# dm646x_cslr_vdce register map
Vendor: Texas Instruments
Peripheral module from a debugger description file.
Registers are 32-bit, access not given, reset 0x0 unless marked. A register's access mark holds for its fields unless they carry their own. Offsets are as the file gives them; lines under a group give offsets from that group; [hi:lo] are bit positions; {n}, {i} and the like mark numbered series; 'fields as' and 'values as' point back to an identical list; <NAME> marks a mode.

## VDCE — Registers for the VDCE module
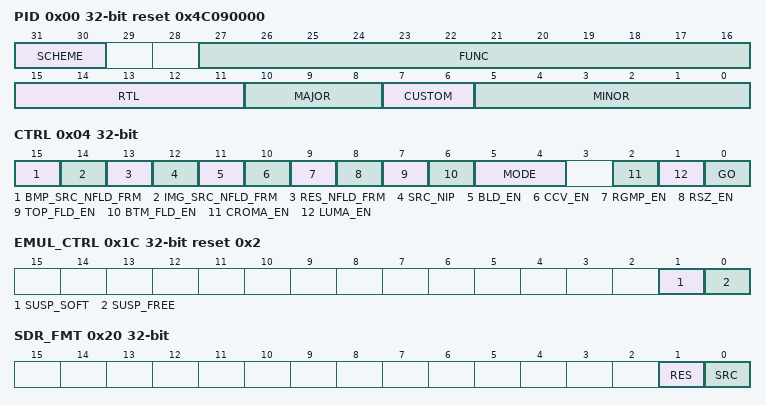
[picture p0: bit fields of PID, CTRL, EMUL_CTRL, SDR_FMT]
0x00 PID reset 0x4C090000
  [31:30] SCHEME ro — Used to distinguish between old scheme and current. Spare bit to encode future schemes. Fixed to be "01"(b)
  [27:16] FUNC ro — Function indicates an S/W compatible module family. If there is not level of S/W compatibility, a new Func number (and hence PID) should be assigned
  [15:11] RTL ro — Indicates RTL version
  [10:8] MAJOR ro — Local revision number which should be owned by module designer. This number should be updated for each major design change (such as bug fix, and memory size change etc ). In present design, fixed to be 0
  [7:6] CUSTOM ro — Indicates a special version for a particular device. Consequence of use may avoid use of standard chip support library (CSL). In this module, fixed to be 0.
  [5:0] MINOR ro — Local revision number which should be owned by module designer. This number should be updated for each small design change. In present design, fixed to be 0.
0x04 CTRL — Control Register
  [15] BMP_SRC_NFLD_FRM rw — Storage format of source artificial bitmap image data in SDRAM 0: field storage format 1: frame storage format
    0=FIELD_STORE (field storage format); 1=FRAME_STORE (frame storage format)
  [14] IMG_SRC_NFLD_FRM rw — Storage format of source data in SDRAM 0: field storage format 1: frame storage format
    values as BMP_SRC_NFLD_FRM
  [13] RES_NFLD_FRM rw — Storage format of result data in SDRAM 0: field storage format 1: frame storage format
    values as BMP_SRC_NFLD_FRM
  [12] SRC_NIP rw — Processing method of each picture data 0: interlaced format (processing based on field format). 1: progressive format (processing based on frame format).
    0=INTERLACE (Interlaced format); 1=PROGRESSIVE (Progressive format)
  [11] BLD_EN rw — 256-step blender function (BLD) activation control register 0 : 256-step BLD is not activated. 1: 256-step BLD is activated.
    0=INACTIVATE (256-step BLD is not activated); 1=ACTIVATE (256-step BLD is activated)
  [10] CCV_EN rw — Chrominance format conversion (CCV) activation control register 0 :CCV is not activated. 1:CCV is activated.
    0=INACTIVATE (CCV is not activated); 1=ACTIVATE (CCV is activated)
  [9] RGMP_EN rw — Range mapping function (RGMP: for VC-1 advanced profile) activation control register 0: RGMP is not activated 1: RGMP is activated
    0=INACTIVATE (RGMP is not activated); 1=ACTIVATE (RGMP is activated)
  [8] RSZ_EN rw — Resize function (RSZ) activation control register 0: RSZ is not activated 1: RSZ is activated
    0=INACTIVATE (RSZ is not activated); 1=ACTIVATE (RSZ is activated)
  [7] TOP_FLD_EN rw — This bit defines "enable" or "disable" of image processing for top-field on GE module 0: top-field processing disable 1: top-field processing enable.
    0=DISABLE (top-field processing disable); 1=ENABLE (top-field processing enable)
  [6] BTM_FLD_EN rw — This bit defines "enable" or "disable" of image processing for bottom-field on GE module 0: bottom-field processing disable 1: bottom-field processing enable.
    0=DISABLE (bottom-field processing disable); 1=ENABLE (bottom-field processing enable)
  [5:4] MODE rw — Performance mode register 00: Edge Padding 01: Trans-code mode (reference to reference) 10: Pre-Codec mode (video input to reference) 11: Post-Codec mode (video output to reference)
  [2] CROMA_EN rw — The Graphic Engine processes chrominance data of the targeted frame 0:Chrominance processing disable 1:Chrominance processing enable
    0=DISABLE (Chrominance processing disable); 1=ENABLE (Chrominance processing enable)
  [1] LUMA_EN rw — The Graphic Engine processes luminance data of the targeted frame 0:Luminance processing disable 1:Luminance processing enable
    0=DISABLE (Luminance processing disable); 1=ENABLE (Luminance processing enable)
  [0] GO rw — GE Module status register 0: GE module is in idle 1:GE module is busy
    0=IDLE (GE module is in idle); 1=BUSY (GE module is busy)
0x08 INTEN — Interrupt enable control register
  [0] INTEN rw — This bit controls preparation to activate interrupt from this module to ARM processor 0: Interrupt disable. 1: Interrupt enable.
    0=DISABLE (Interrupt disable); 1=ENABLE (Interrupt enable)
0x0C INTEN_SET — Interrupt assertion function activation register to ARM
  [0] SET rw — Interrupt assertion function activation register to ARM 0: Interrupt inactivated (cannot write 0). 1: Interrupt activated.
    0=INACTIVATE (Interrupt inactivated); 1=ACTIVATE (Interrupt activated)
0x10 INTEN_CLR — Interrupt enable clear register
  [0] CLR wo — Interrupt enable clear register 0: No change. 1: Interrupt inactivated (cannot be read by ARM).
    0=NO_CHANGE; 1=INACTIVATE (Interrupt inactivated)
0x14 STATUS — Interrupt status register
  [0] STATUS ro — Interrupt status register 0: Configured one frame processing is under way. 1: Configured one frame processing is finished, and not checked yet.
    0=PROCESS (Configured one frame processing is under way.); 1=FINISHED (Configured one frame processing is finished, and not checked yet.)
0x18 STAT_CLR — Interrupt status clear register
  [0] CLR wo — Interrupt status clear register bit 0: No change. 1: ge_status clear register (write only: cannot be read)
    0=NO_CHANGE; 1=STAT_CLR (ge_status clear register)
0x1C EMUL_CTRL reset 0x2 — Emulation control register
  [1] SUSP_SOFT ro — This bit defines whether or not a soft or hard stop is initiated whenever the "emususp" is asserted. 0: Hard stop 1: soft stop
    0=HDSTP (Hard Stop); 1=SFSTP (Soft Stop)
  [0] SUSP_FREE rw — This bit controls whether or not the peripheral will respond to the emulation suspend signal that it has been programmed to monitor. 0: functions based on configuration of "ge_emulsusp_soft". 1: ignores any emulation suspend signal (non-stop).
    0=SUSP_SOFT (functions based on configuration of "ge_emulsusp_soft".); 1=IGNORE (ignores any emulation suspend signal (non-stop).)
0x20 SDR_FMT — SDRAM data storage format register
  [1] RES rw — SDRAM data storage format for result of the GE module 0: raster scanning mode 1: sub-picture mode
    0=RASTER_MODE (Raster scanning mode); 1=SUBPIC_MODE (Sub-picture scanning mode)
  [0] SRC rw — SDRAM data storage format for source data used in GE module 0: raster scanning mode 1: sub-picture mode
    values as RES
0x24 REQ_SZ — Request unit size for DMA data transfer from/to SDRAM
  [8:0] REQ_SZ rw — This register defines request unit size for DMA data transfer from/to SDRAM "000100000": 32[byte] "001000000": 64[byte] "010000000": 128[byte] "100000000": 256[byte]
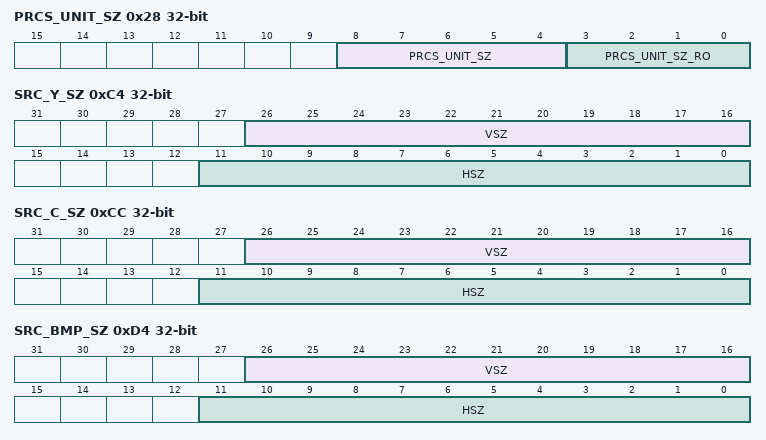
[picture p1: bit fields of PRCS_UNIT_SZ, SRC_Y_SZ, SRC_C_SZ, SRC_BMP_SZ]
0x28 PRCS_UNIT_SZ — Processing unit size to be generated in Horizontal direction
  [8:4] PRCS_UNIT_SZ rw — This register defines Processing unit size to be generated in Horizontal direction "00001": 16[byte] "00010": 32[byte] "00100": 64[byte] "01000": 128[byte] "10000": 256[byte]
  [3:0] PRCS_UNIT_SZ_RO ro — Reserved
0x40 SRC_STRT_ADD_YTOP rw — Start address of source picture area which is prepared for luminance data in top field on SDRAM
  [31:0] ST_ADD
0x44 SRC_SP_HSZ_YTOP — Horizontal sub-picture size for top-field luminance data which is stored in SDRAM as source data
  [8:0] SP_HSZ rw — Horizontal sub-picture size for top-field luminance data which is stored in SDRAM as source data 000010000: 16[pixel] 000100000: 32[pixel] 001000000: 64[pixel] 010000000: 128[pixel] 100000000: 256[pixel]
0x48 SRC_ADD_OFST_YTOP rw — This register configures address offset value of each line for top field luminance data on raster store format
  [31:0] ADD_OFST
0x4C SRC_STRT_ADD_YBTM rw — Start address of source picture area which is prepared for luminance data in bottom field on SDRAM.
  [31:0] ST_ADD
0x50 SRC_SP_HSZ_YBTM — Horizontal sub-picture size for bottom-field luminance data which is stored in SDRAM as source data
  [8:0] SP_HSZ rw — Horizontal sub-picture size for bottom-field luminance data which is stored in SDRAM as source data 000010000: 16[pixel] 000100000: 32[pixel] 001000000: 64[pixel] 010000000: 128[pixel] 100000000: 256[pixel]
0x54 SRC_ADD_OFST_YBTM rw — Address offset value of each line for bottom field luminance data on raster store format
  [31:0] ADD_OFST — Address offset value of each line for bottom field luminance data on raster store format.
0x58 SRC_STRT_ADD_CTOP rw — Start address of source picture area which is prepared for chrominance data in top field on SDRAM
  [31:0] ST_ADD
0x5C SRC_SP_HSZ_CTOP — Horizontal sub-picture size for top-field chrominance data which is stored in SDRAM as source data
  [8:0] SP_HSZ rw — Horizontal sub-picture size for top-field chrominance data which is stored in SDRAM as source data 000010000: 16[pixel] 000100000: 32[pixel] 001000000: 64[pixel] 010000000: 128[pixel] 100000000: 256[pixel]
0x60 SRC_ADD_OFST_CTOP rw — This register configures address offset value of each line for top field chrominance data on raster store format
  [31:0] ADD_OFST
0x64 SRC_STRT_ADD_CBTM rw — Start address of source picture area which is prepared for chrominance data in bottom field on SDRAM
  [31:0] ST_ADD
0x68 SRC_SP_HSZ_CBTM — Horizontal sub-picture size for bottom-field chrominance data which is stored in SDRAM as source data
  [8:0] SP_HSZ rw — Horizontal sub-picture size for bottom-field chrominance data which is stored in SDRAM as source data 000010000: 16[pixel] 000100000: 32[pixel] 001000000: 64[pixel] 010000000: 128[pixel] 100000000: 256[pixel]
0x6C SRC_ADD_OFST_CBTM rw — Address offset value of each line for bottom field chrominance data on raster store format
  [31:0] ADD_OFST — Address offset value of each line for bottom field chrominance data on raster store format.
0x70 SRC_STRT_ADD_BMP_TOP rw — Start address of source picture area, which is prepared for bitmap data in top field on SDRAM
  [31:0] ST_ADD
0x74 SRC_ADD_OFST_BMP_TOP rw — Address offset value of each line for top field bitmap data on raster store format
  [31:0] ADD_OFST
0x78 SRC_STRT_ADD_BMP_BTM rw — Start address of source picture area which is prepared for bitmap data in bottom field on SDRAM
  [31:0] ST_ADD
0x7C SRC_ADD_OFST_BMP_BTM rw — Address offset value of each line for bottom field bitmap data on raster store format
  [31:0] ADD_OFST
0x80 RES_STRT_ADD_YTOP rw — Start address of result picture area which is prepared for luminance data in top field on SDRAM
  [31:0] ST_ADD
0x84 RES_SP_HSZ_YTOP — Horizontal sub-picture size for top-field luminance data which is stored in SDRAM as result data
  [8:0] SP_HSZ rw — Horizontal sub-picture size for top-field luminance data which is stored in SDRAM as result data 000010000: 16[pixel] 000100000: 32[pixel] 001000000: 64[pixel] 010000000: 128[pixel] 100000000: 256[pixel]
0x88 RES_ADD_OFST_YTOP rw — This register configures address offset value of each line for top field luminance data on raster store format
  [31:0] ADD_OFST
0x8C RES_STRT_ADD_YBTM rw — Start address of result picture area which is prepared for luminance data in bottom field on SDRAM.
  [31:0] ST_ADD
0x90 RES_SP_HSZ_YBTM — Horizontal sub-picture size for bottom-field luminance data which is stored in SDRAM as result data
  [8:0] SP_HSZ rw — Horizontal sub-picture size for bottom-field luminance data which is stored in SDRAM as result data 000010000: 16[pixel] 000100000: 32[pixel] 001000000: 64[pixel] 010000000: 128[pixel] 100000000: 256[pixel]
0x94 RES_ADD_OFST_YBTM rw — Address offset value of each line for bottom field luminance data on raster store format
  fields as SRC_ADD_OFST_YBTM
0x98 RES_STRT_ADD_CTOP rw — Start address of result picture area which is prepared for chrominance data in top field on SDRAM
  [31:0] ST_ADD
0x9C RES_SP_HSZ_CTOP — Horizontal sub-picture size for top-field chrominance data which is stored in SDRAM as result data
  [8:0] SP_HSZ rw — Horizontal sub-picture size for top-field chrominance data which is stored in SDRAM as result data 000010000: 16[pixel] 000100000: 32[pixel] 001000000: 64[pixel] 010000000: 128[pixel] 100000000: 256[pixel]
0xA0 RES_ADD_OFST_CTOP rw — This register configures address offset value of each line for top field chrominance data on raster store format
  [31:0] ADD_OFST
0xA4 RES_STRT_ADD_CBTM rw — Start address of result picture area which is prepared for chrominance data in bottom field on SDRAM
  [31:0] ST_ADD
0xA8 RES_SP_HSZ_CBTM — Horizontal sub-picture size for bottom-field chrominance data which is stored in SDRAM as result data
  [8:0] SP_HSZ rw — Horizontal sub-picture size for bottom-field chrominance data which is stored in SDRAM as result data 000010000: 16[pixel] 000100000: 32[pixel] 001000000: 64[pixel] 010000000: 128[pixel] 100000000: 256[pixel]
0xAC RES_ADD_OFST_CBTM rw — Address offset value of each line for bottom field chrominance data on raster store format
  fields as SRC_ADD_OFST_CBTM
0xC0 SRC_Y_STRT_PS — Horizontal start position of source luminance image data
  [7:0] HPS rw — This bit defines horizontal start position of source luminance image data
0xC4 SRC_Y_SZ — Size of source luminance image data
  [26:16] VSZ rw — This bit defines vertical size of source luminance image data.
  [11:0] HSZ rw — This bit defines horizontal size of source luminance image data.
0xC8 SRC_C_STRT_PS — Horizontal start position of source Chrominance image data
  [7:0] HPS rw — This bit defines horizontal start position of source Chrominance image data
0xCC SRC_C_SZ — Size of source Chrominance image data
  [26:16] VSZ rw — This bit defines vertical size of source Chrominance image data.
  [11:0] HSZ rw — This bit defines horizontal size of source Chrominance image data.
0xD0 SRC_BMP_STRT_PS — Horizontal start position of BLD source image data
  [4:0] HPS rw — This bit defines horizontal start position of BLD source image data
0xD4 SRC_BMP_SZ — Size of BLD source image data
  [26:16] VSZ rw — This bit defines vertical size of BLD source image data.
  [11:0] HSZ rw — This bit defines horizontal size of BLD source image data.
0xE0 RES_Y_STRT_PS — Horizontal start position of result luminance image data
  [7:0] HPS rw — This bit defines horizontal start position of result luminance image data
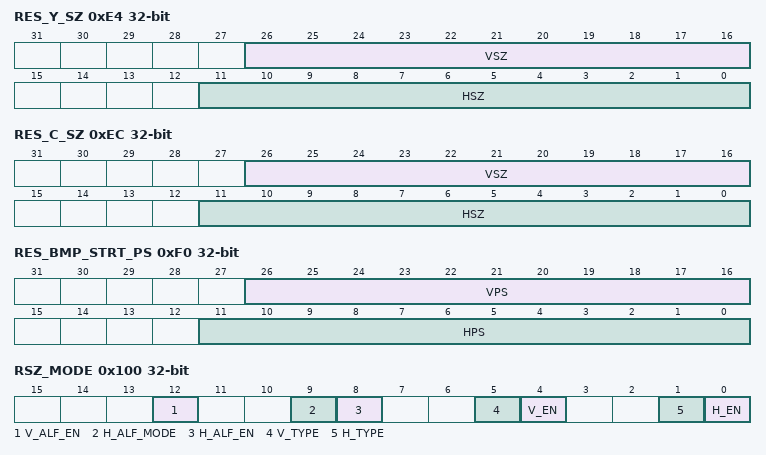
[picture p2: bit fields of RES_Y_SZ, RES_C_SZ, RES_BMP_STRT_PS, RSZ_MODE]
0xE4 RES_Y_SZ — Size of result luminance image data
  [26:16] VSZ rw — This bit defines vertical size of result luminance image data.
  [11:0] HSZ rw — This bit defines horizontal size of result luminance image data.
0xE8 RES_C_STRT_PS — Horizontal start position of result Chrominance image data
  [7:0] HPS rw — This bit defines horizontal start position of result Chrominance image data
0xEC RES_C_SZ — Size of result Chrominance image data
  [26:16] VSZ rw — This bit defines vertical size of result Chrominance image data.
  [11:0] HSZ rw — This bit defines horizontal size of result Chrominance image data.
0xF0 RES_BMP_STRT_PS — Start position of bitmap window to be blended to image data
  [26:16] VPS rw — This bit defines vertical start position of bitmap window to be blended to image data
  [11:0] HPS rw — This bit defines horizontal start position of bitmap window to be blended to image data
0x100 RSZ_MODE — Resize mode register
  [12] V_ALF_EN rw — Vertical anti-alias filter control bit 0: vertical anti-alias filter is inactive. 1: vertical anti-alias filter is active.
    0=INACTIVATE (vertical anti-alias filter is inactive.); 1=ACTIVATE (vertical anti-alias filter is active)
  [9] H_ALF_MODE rw — Anti-alias filter mode control bit 0: automatic calculated value for weight coefficient. 1: manual input for weight coefficient.
    0=AUTOMATIC (automatic calculated value for weight coefficient); 1=MANUAL (manual input for weight coefficient.)
  [8] H_ALF_EN rw — Horizontal and vertical anti-alias filter control bit 0: anti-alias filter inactive. 1: anti-alias filter active
    0=INACTIVATE (anti-alias filter inactive); 1=ACTIVATE (anti-alias filter active)
  [5] V_TYPE rw — Vertical resize functional type selection bit 0: 4-tap cubic convolution. 1: 4-tap linear interpolation.
    0=4T_CUB_CON (4-tap cubic convolution.); 1=4T_LIN_INT (4-tap linear interpolation.)
  [4] V_EN rw — Vertical resize functional control bit 0: vertical resize disable 1: vertical resize enable
    0=DISABLE (vertical resize disable); 1=ENABLE (vertical resize enable)
  [1] H_TYPE rw — Horizontal resize functional type selection bit 0: 4-tap cubic convolution. 1: 4-tap linear interpolation.
    values as V_TYPE
  [0] H_EN rw — Horizontal resize functional control bit 0: Horizontal resize disable 1: Horizontal resize enable
    0=DISABLE (Horizontal resize disable); 1=ENABLE (Horizontal resize enable)
0x104 RSZ_H_MAG — Resize magnification ratio for horizontal direction register
  [11:0] H rw — Resize magnification ratio for horizontal direction
0x108 RSZ_V_MAG — Resize magnification ratio for vertical direction register
  [11:0] V rw
0x10C RSZ_H_PHASE — Horizontal Phase displacement of first resized output pixel position from first pixel in source image
  [8:0] H rw
0x110 RSZ_V_PHASE — Vertical Phase displacement of first resized output pixel position from first pixel in source image
  [9:0] V rw
0x114 RSZ_INTNST — Intensity of horizontal anti-aliasing filter
  [7:0] ALF rw
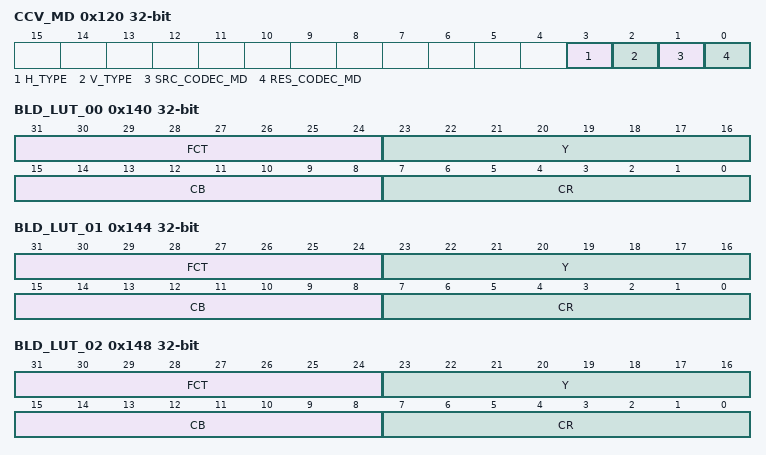
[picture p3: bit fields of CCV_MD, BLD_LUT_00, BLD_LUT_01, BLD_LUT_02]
0x120 CCV_MD — CCV mode register
  [3] H_TYPE rw — Horizontal chrominance conversion functional type selection bit 0 :4-tap cubic convolution. 1:4-tap linear interpolation
    values as RSZ_MODE.V_TYPE
  [2] V_TYPE rw — Vertical chrominance conversion functional type selection bit 0 :4-tap cubic convolution. 1:4-tap linear interpolation
    values as RSZ_MODE.V_TYPE
  [1] SRC_CODEC_MD rw — Mode control for chrominance conversion of source data 0:chrominance conversion on MPEG-2/MPEG-4/H.264/VC-1 1:chrominance conversion on MPEG-1
    0=MPEG_2_4_H264_VC1 (chrominance conversion on MPEG-2/MPEG-4/H.264/VC-1); 1=MPEG_1 (chrominance conversion on MPEG-1)
  [0] RES_CODEC_MD rw — Mode control for chrominance conversion of result data 0:chrominance conversion on MPEG-2/MPEG-4/H.264/VC-1 1:chrominance conversion on MPEG-1
    values as SRC_CODEC_MD
0x140 BLD_LUT_00 rw — 256-Step Blender Control LUT register 0
  [31:24] FCT — Blend factor for color defined in index value "00(b)".
  [23:16] Y — Luminance data for color defined in index value "00(b)".
  [15:8] CB — Chrominance (Cb) data for color defined in index value "00(b)".
  [7:0] CR — Chrominance (Cr) data for color defined in index value "00(b)".
0x144 BLD_LUT_01 rw — 256-Step Blender Control LUT register 1
  [31:24] FCT — Blend factor for color defined in index value "01(b)".
  [23:16] Y — Luminance data for color defined in index value "01(b)".
  [15:8] CB — Chrominance (Cb) data for color defined in index value "01(b)".
  [7:0] CR — Chrominance (Cr) data for color defined in index value "01(b)".
0x148 BLD_LUT_02 rw — 256-Step Blender Control LUT register 2
  [31:24] FCT — Blend factor for color defined in index value "10(b)".
  [23:16] Y — Luminance data for color defined in index value "10(b)".
  [15:8] CB — Chrominance (Cb) data for color defined in index value "10(b)".
  [7:0] CR — Chrominance (Cr) data for color defined in index value "10(b)".
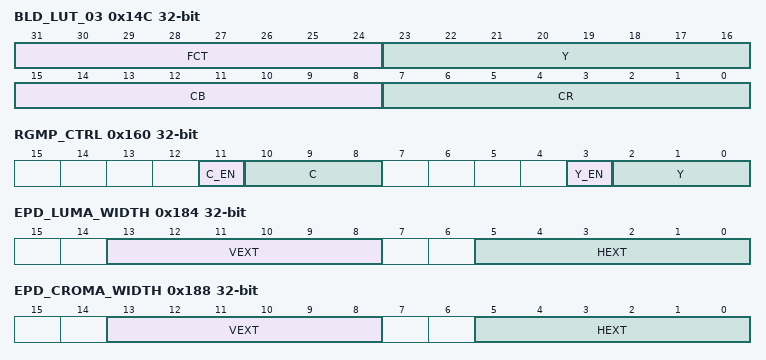
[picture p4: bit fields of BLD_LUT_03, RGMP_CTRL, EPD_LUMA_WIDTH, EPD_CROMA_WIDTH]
0x14C BLD_LUT_03 rw — 256-Step Blender Control LUT register 3
  [31:24] FCT — Blend factor for color defined in index value "11(b)".
  [23:16] Y — Luminance data for color defined in index value "11(b)".
  [15:8] CB — Chrominance (Cb) data for color defined in index value "11(b)".
  [7:0] CR — Chrominance (Cr) data for color defined in index value "11(b)".
0x160 RGMP_CTRL — Range mapping control register
  [11] C_EN rw — Control bit for range mapping on chrominance 0: chrominance range mapping disable. 1: chrominance range mapping enable
    0=DISABLE (chrominance range mapping disable.); 1=ENABLE (chrominance range mapping enable)
  [10:8] C rw — Coefficient for multiplier of equation to calculate chrominance pixel value for range mapping
  [3] Y_EN rw — Control bit for range mapping on luminance 0: luminance range mapping disable. 1: luminance range mapping enable
    0=DISABLE (luminance range mapping disable.); 1=ENABLE (luminance range mapping enable)
  [2:0] Y rw — Coefficient for multiplier of equation to calculate luminance pixel value for range mapping
0x184 EPD_LUMA_WIDTH — Extension width of edge padding function for luminance field data in SDRAM
  [13:8] VEXT rw — Vertical extension width of edge padding function for luminance field data in SDRAM
  [5:0] HEXT rw — Horizontal extension width of edge padding function for luminance field data in SDRAM
0x188 EPD_CROMA_WIDTH — Extension width of edge padding function for chrominance field data in SDRAM
  [13:8] VEXT rw — Vertical extension width of edge padding function for chrominance field data in SDRAM
  [5:0] HEXT rw — Horizontal extension width of edge padding function for chrominance field data in SDRAM
